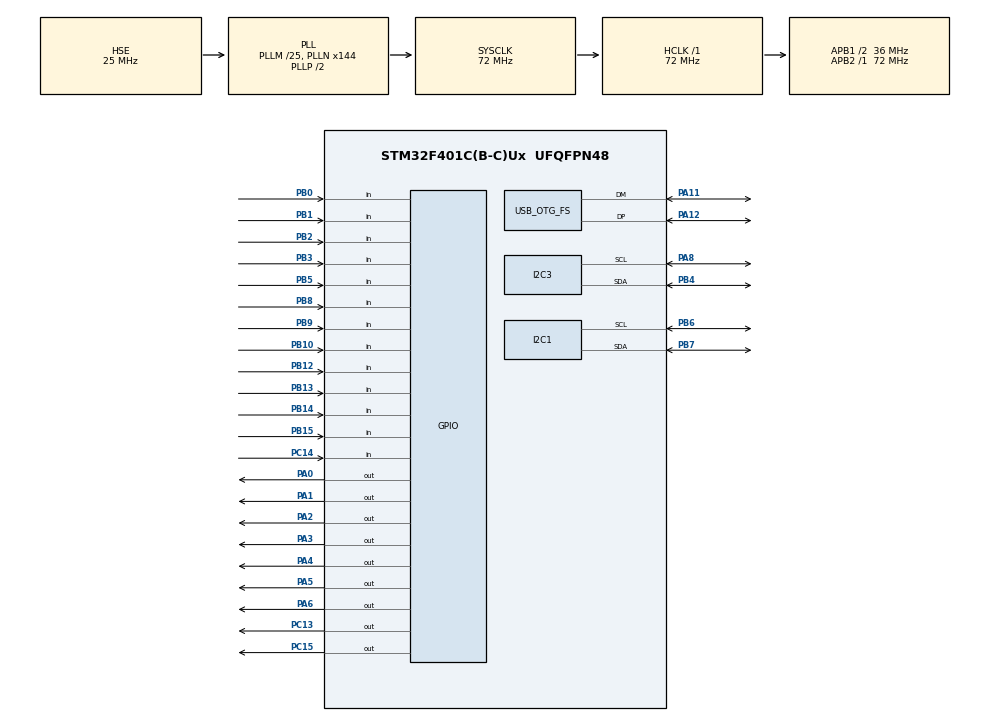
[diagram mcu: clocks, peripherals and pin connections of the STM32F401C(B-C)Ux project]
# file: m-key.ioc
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I2C1.I2C_Mode=I2C_Standard
Mcu.Family=STM32F4
Mcu.Name=STM32F401C(B-C)Ux
Mcu.Package=UFQFPN48
NVIC.OTG_FS_IRQn=true\:0\:0\:false\:false\:true\:false\:true\:true
NVIC.PriorityGroup=NVIC_PRIORITYGROUP_4
PA0-WKUP.GPIO_PuPd=GPIO_PULLDOWN
PA0-WKUP.Signal=GPIO_Output
PA1.GPIO_PuPd=GPIO_PULLDOWN
PA1.GPIO_Speed=GPIO_SPEED_FREQ_VERY_HIGH
PA1.Signal=GPIO_Output
PA11.Mode=Device_Only
PA11.Signal=USB_OTG_FS_DM
PA12.Mode=Device_Only
PA12.Signal=USB_OTG_FS_DP
PA2.GPIO_PuPd=GPIO_PULLDOWN
PA2.GPIO_Speed=GPIO_SPEED_FREQ_VERY_HIGH
PA2.Signal=GPIO_Output
PA3.GPIO_PuPd=GPIO_PULLDOWN
PA3.GPIO_Speed=GPIO_SPEED_FREQ_VERY_HIGH
PA3.Signal=GPIO_Output
PA4.GPIO_PuPd=GPIO_PULLDOWN
PA4.GPIO_Speed=GPIO_SPEED_FREQ_VERY_HIGH
PA4.Signal=GPIO_Output
PA5.GPIO_PuPd=GPIO_PULLDOWN
PA5.GPIO_Speed=GPIO_SPEED_FREQ_VERY_HIGH
PA5.Signal=GPIO_Output
PA6.GPIO_PuPd=GPIO_PULLDOWN
PA6.Signal=GPIO_Output
PA8.Mode=I2C
PA8.Signal=I2C3_SCL
PB0.GPIO_PuPd=GPIO_PULLDOWN
PB0.Signal=GPIO_Input
PB1.GPIO_PuPd=GPIO_PULLDOWN
PB1.Signal=GPIO_Input
PB10.GPIO_PuPd=GPIO_PULLDOWN
PB10.Signal=GPIO_Input
PB12.GPIO_PuPd=GPIO_PULLDOWN
PB12.Signal=GPIO_Input
PB13.GPIO_PuPd=GPIO_PULLDOWN
PB13.Signal=GPIO_Input
PB14.GPIO_PuPd=GPIO_PULLDOWN
PB14.Signal=GPIO_Input
PB15.GPIO_PuPd=GPIO_PULLDOWN
PB15.Signal=GPIO_Input
PB2.GPIO_PuPd=GPIO_PULLDOWN
PB2.Signal=GPIO_Input
PB3.GPIO_PuPd=GPIO_PULLDOWN
PB3.Signal=GPIO_Input
PB4.Mode=I2C
PB4.Signal=I2C3_SDA
PB5.GPIO_PuPd=GPIO_PULLDOWN
PB5.Signal=GPIO_Input
PB6.Mode=I2C
PB6.Signal=I2C1_SCL
PB7.Mode=I2C
PB7.Signal=I2C1_SDA
PB8.GPIO_PuPd=GPIO_PULLDOWN
PB8.Signal=GPIO_Input
PB9.GPIO_PuPd=GPIO_PULLDOWN
PB9.Signal=GPIO_Input
PC13-ANTI_TAMP.GPIO_PuPd=GPIO_PULLDOWN
PC13-ANTI_TAMP.Signal=GPIO_Output
PC14-OSC32_IN.GPIO_PuPd=GPIO_PULLDOWN
PC14-OSC32_IN.Signal=GPIO_Input
PC15-OSC32_OUT.GPIO_PuPd=GPIO_PULLDOWN
PC15-OSC32_OUT.Signal=GPIO_Output
PH0\ -\ OSC_IN.Mode=HSE-External-Oscillator
PH0\ -\ OSC_IN.Signal=RCC_OSC_IN
PH1\ -\ OSC_OUT.Mode=HSE-External-Oscillator
PH1\ -\ OSC_OUT.Signal=RCC_OSC_OUT
ProjectManager.HeapSize=0x200
ProjectManager.StackSize=0x400
ProjectManager.TargetToolchain=Makefile
RCC.48MHZClocksFreq_Value=48000000
RCC.AHBFreq_Value=72000000
RCC.APB1CLKDivider=RCC_HCLK_DIV2
RCC.APB1Freq_Value=36000000
RCC.APB1TimFreq_Value=72000000
RCC.APB2Freq_Value=72000000
RCC.APB2TimFreq_Value=72000000
RCC.CortexFreq_Value=72000000
RCC.HCLKFreq_Value=72000000
RCC.HSE_VALUE=25000000
RCC.HSI_VALUE=16000000
RCC.LSE_VALUE=32768
RCC.PLLM=25
RCC.PLLN=144
RCC.PLLQ=3
RCC.SYSCLKFreq_VALUE=72000000
RCC.SYSCLKSource=RCC_SYSCLKSOURCE_PLLCLK
RCC.VCOOutputFreq_Value=144000000
TIM11.Period=65536 - 1
TIM11.Prescaler=7200 - 1
USB_DEVICE.CLASS_NAME_FS=HID
USB_DEVICE.MANUFACTURER_STRING=Morel
USB_DEVICE.PRODUCT_STRING_HID_FS=STM32 m-key
USB_DEVICE.VirtualMode=Hid
USB_DEVICE.VirtualModeFS=Hid_FS
USB_OTG_FS.VirtualMode=Device_Only
VP_TIM11_VS_ClockSourceINT.Mode=Enable_Timer
VP_USB_DEVICE_VS_USB_DEVICE_HID_FS.Mode=HID_FS
board=custom

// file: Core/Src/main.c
/* USER CODE BEGIN Header */
/**
  ******************************************************************************
  * @file           : main.c
  * @brief          : Main program body
  ******************************************************************************
  * @attention
  *
  * Copyright (c) 2023 STMicroelectronics.
  * All rights reserved.
  *
  * This software is licensed under terms that can be found in the LICENSE file
  * in the root directory of this software component.
  * If no LICENSE file comes with this software, it is provided AS-IS.
  *
  ******************************************************************************
  */
/* USER CODE END Header */
#include "main.h"
#include "usb_device.h"

/* USER CODE BEGIN Includes */

#include "core.h"

/* USER CODE END Includes */

I2C_HandleTypeDef hi2c1;
I2C_HandleTypeDef hi2c3;

TIM_HandleTypeDef htim11;

void SystemClock_Config(void);
static void MX_GPIO_Init(void);
static void MX_TIM11_Init(void);
static void MX_I2C1_Init(void);
static void MX_I2C3_Init(void);

int main(void)
{

  /* MCU Configuration--------------------------------------------------------*/

  /* Reset of all peripherals, Initializes the Flash interface and the Systick. */
  HAL_Init();

  /* Configure the system clock */
  SystemClock_Config();

  /* Initialize all configured peripherals */
  MX_GPIO_Init();
  MX_USB_DEVICE_Init();
  MX_TIM11_Init();
  MX_I2C1_Init();
  MX_I2C3_Init();
  /* USER CODE BEGIN 2 */
  user_main();

  /* USER CODE END 2 */

  /* Infinite loop */
  while (1)
  {

  }
}

void SystemClock_Config(void)
{
  RCC_OscInitTypeDef RCC_OscInitStruct = {0};
  RCC_ClkInitTypeDef RCC_ClkInitStruct = {0};

  /** Configure the main internal regulator output voltage
  */
  __HAL_RCC_PWR_CLK_ENABLE();
  __HAL_PWR_VOLTAGESCALING_CONFIG(PWR_REGULATOR_VOLTAGE_SCALE2);

  /** Initializes the RCC Oscillators according to the specified parameters
  * in the RCC_OscInitTypeDef structure.
  */
  RCC_OscInitStruct.OscillatorType = RCC_OSCILLATORTYPE_HSE;
  RCC_OscInitStruct.HSEState = RCC_HSE_ON;
  RCC_OscInitStruct.PLL.PLLState = RCC_PLL_ON;
  RCC_OscInitStruct.PLL.PLLSource = RCC_PLLSOURCE_HSE;
  RCC_OscInitStruct.PLL.PLLM = 25;
  RCC_OscInitStruct.PLL.PLLN = 144;
  RCC_OscInitStruct.PLL.PLLP = RCC_PLLP_DIV2;
  RCC_OscInitStruct.PLL.PLLQ = 3;
  if (HAL_RCC_OscConfig(&RCC_OscInitStruct) != HAL_OK)
  {
    Error_Handler();
  }

  /** Initializes the CPU, AHB and APB buses clocks
  */
  RCC_ClkInitStruct.ClockType = RCC_CLOCKTYPE_HCLK|RCC_CLOCKTYPE_SYSCLK
                              |RCC_CLOCKTYPE_PCLK1|RCC_CLOCKTYPE_PCLK2;
  RCC_ClkInitStruct.SYSCLKSource = RCC_SYSCLKSOURCE_PLLCLK;
  RCC_ClkInitStruct.AHBCLKDivider = RCC_SYSCLK_DIV1;
  RCC_ClkInitStruct.APB1CLKDivider = RCC_HCLK_DIV2;
  RCC_ClkInitStruct.APB2CLKDivider = RCC_HCLK_DIV1;

  if (HAL_RCC_ClockConfig(&RCC_ClkInitStruct, FLASH_LATENCY_2) != HAL_OK)
  {
    Error_Handler();
  }
}

static void MX_I2C1_Init(void)
{

  hi2c1.Instance = I2C1;
  hi2c1.Init.ClockSpeed = 100000;
  hi2c1.Init.DutyCycle = I2C_DUTYCYCLE_2;
  hi2c1.Init.OwnAddress1 = 0;
  hi2c1.Init.AddressingMode = I2C_ADDRESSINGMODE_7BIT;
  hi2c1.Init.DualAddressMode = I2C_DUALADDRESS_DISABLE;
  hi2c1.Init.OwnAddress2 = 0;
  hi2c1.Init.GeneralCallMode = I2C_GENERALCALL_DISABLE;
  hi2c1.Init.NoStretchMode = I2C_NOSTRETCH_DISABLE;
  if (HAL_I2C_Init(&hi2c1) != HAL_OK)
  {
    Error_Handler();
  }

}

static void MX_I2C3_Init(void)
{

  hi2c3.Instance = I2C3;
  hi2c3.Init.ClockSpeed = 100000;
  hi2c3.Init.DutyCycle = I2C_DUTYCYCLE_2;
  hi2c3.Init.OwnAddress1 = 0;
  hi2c3.Init.AddressingMode = I2C_ADDRESSINGMODE_7BIT;
  hi2c3.Init.DualAddressMode = I2C_DUALADDRESS_DISABLE;
  hi2c3.Init.OwnAddress2 = 0;
  hi2c3.Init.GeneralCallMode = I2C_GENERALCALL_DISABLE;
  hi2c3.Init.NoStretchMode = I2C_NOSTRETCH_DISABLE;
  if (HAL_I2C_Init(&hi2c3) != HAL_OK)
  {
    Error_Handler();
  }

}

static void MX_TIM11_Init(void)
{

  htim11.Instance = TIM11;
  htim11.Init.Prescaler = 7200 - 1;
  htim11.Init.CounterMode = TIM_COUNTERMODE_UP;
  htim11.Init.Period = 65536 - 1;
  htim11.Init.ClockDivision = TIM_CLOCKDIVISION_DIV1;
  htim11.Init.AutoReloadPreload = TIM_AUTORELOAD_PRELOAD_DISABLE;
  if (HAL_TIM_Base_Init(&htim11) != HAL_OK)
  {
    Error_Handler();
  }

}

static void MX_GPIO_Init(void)
{
  GPIO_InitTypeDef GPIO_InitStruct = {0};

  /* GPIO Ports Clock Enable */
  __HAL_RCC_GPIOC_CLK_ENABLE();
  __HAL_RCC_GPIOH_CLK_ENABLE();
  __HAL_RCC_GPIOA_CLK_ENABLE();
  __HAL_RCC_GPIOB_CLK_ENABLE();

  /*Configure GPIO pin Output Level */
  HAL_GPIO_WritePin(GPIOC, GPIO_PIN_13|GPIO_PIN_15, GPIO_PIN_RESET);

  /*Configure GPIO pin Output Level */
  HAL_GPIO_WritePin(GPIOA, GPIO_PIN_0|GPIO_PIN_1|GPIO_PIN_2|GPIO_PIN_3
                          |GPIO_PIN_4|GPIO_PIN_5|GPIO_PIN_6, GPIO_PIN_RESET);

  /*Configure GPIO pins : PC13 PC15 */
  GPIO_InitStruct.Pin = GPIO_PIN_13|GPIO_PIN_15;
  GPIO_InitStruct.Mode = GPIO_MODE_OUTPUT_PP;
  GPIO_InitStruct.Pull = GPIO_PULLDOWN;
  GPIO_InitStruct.Speed = GPIO_SPEED_FREQ_LOW;
  HAL_GPIO_Init(GPIOC, &GPIO_InitStruct);

  /*Configure GPIO pin : PC14 */
  GPIO_InitStruct.Pin = GPIO_PIN_14;
  GPIO_InitStruct.Mode = GPIO_MODE_INPUT;
  GPIO_InitStruct.Pull = GPIO_PULLDOWN;
  HAL_GPIO_Init(GPIOC, &GPIO_InitStruct);

  /*Configure GPIO pins : PA0 PA6 */
  GPIO_InitStruct.Pin = GPIO_PIN_0|GPIO_PIN_6;
  GPIO_InitStruct.Mode = GPIO_MODE_OUTPUT_PP;
  GPIO_InitStruct.Pull = GPIO_PULLDOWN;
  GPIO_InitStruct.Speed = GPIO_SPEED_FREQ_LOW;
  HAL_GPIO_Init(GPIOA, &GPIO_InitStruct);

  /*Configure GPIO pins : PA1 PA2 PA3 PA4
                           PA5 */
  GPIO_InitStruct.Pin = GPIO_PIN_1|GPIO_PIN_2|GPIO_PIN_3|GPIO_PIN_4
                          |GPIO_PIN_5;
  GPIO_InitStruct.Mode = GPIO_MODE_OUTPUT_PP;
  GPIO_InitStruct.Pull = GPIO_PULLDOWN;
  GPIO_InitStruct.Speed = GPIO_SPEED_FREQ_VERY_HIGH;
  HAL_GPIO_Init(GPIOA, &GPIO_InitStruct);

  /*Configure GPIO pins : PA7 PA9 PA10 PA13
                           PA14 PA15 */
  GPIO_InitStruct.Pin = GPIO_PIN_7|GPIO_PIN_9|GPIO_PIN_10|GPIO_PIN_13
                          |GPIO_PIN_14|GPIO_PIN_15;
  GPIO_InitStruct.Mode = GPIO_MODE_ANALOG;
  GPIO_InitStruct.Pull = GPIO_NOPULL;
  HAL_GPIO_Init(GPIOA, &GPIO_InitStruct);

  /*Configure GPIO pins : PB0 PB1 PB2 PB10
                           PB12 PB13 PB14 PB15
                           PB3 PB5 PB8 PB9 */
  GPIO_InitStruct.Pin = GPIO_PIN_0|GPIO_PIN_1|GPIO_PIN_2|GPIO_PIN_10
                          |GPIO_PIN_12|GPIO_PIN_13|GPIO_PIN_14|GPIO_PIN_15
                          |GPIO_PIN_3|GPIO_PIN_5|GPIO_PIN_8|GPIO_PIN_9;
  GPIO_InitStruct.Mode = GPIO_MODE_INPUT;
  GPIO_InitStruct.Pull = GPIO_PULLDOWN;
  HAL_GPIO_Init(GPIOB, &GPIO_InitStruct);

}

void Error_Handler(void)
{
  __disable_irq();
  while (1)
  {
  }
}
